# tviic2d6mddr register map
Vendor: Cypress Semiconductor; Series: tviic2d6mddr; File version: 1.0
CPU: CM7 r0p1, little endian, MPU, FPU, VTOR, 3 interrupt priority bits
Registers are 32-bit, read-write, reset 0x0 unless marked. A register's access mark holds for its fields unless they carry their own. Offsets are from the block's base; [hi:lo] are bit positions; lines under a group give offsets from that group; {n}, {i} and the like mark numbered series.

## LPDDR40 (part 1 of 5) — LPDDR4
Base 0x404A0000
0x00 LPDDR4_WRAPPER group — HOBTO specific wrapper
  0x00 CTL — Control
    [31] ENABLED — IP enable bit. When the IP is disabled, all retention registers can be accessed (else results in AHB error response). 0: Disabled. 1: Enabled.
      0=DISABLED (N/A); 1=ENABLED (N/A)
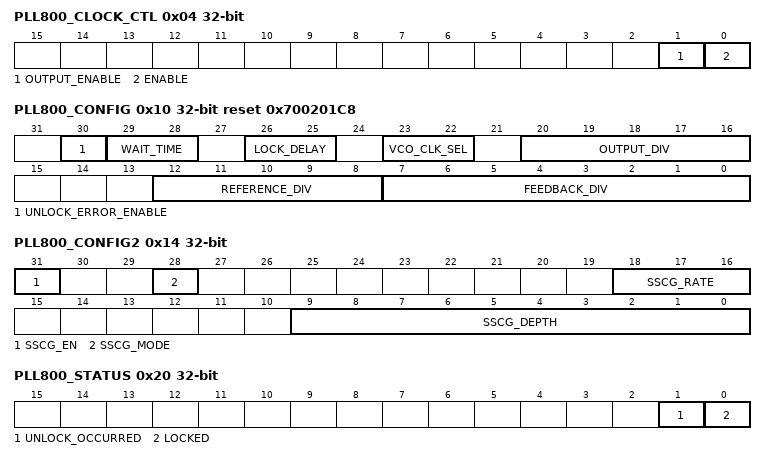
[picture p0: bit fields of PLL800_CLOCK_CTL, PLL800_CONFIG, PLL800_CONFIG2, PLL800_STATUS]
  0x04 PLL800_CLOCK_CTL — 800MHz PLL Control Register
    [1] OUTPUT_ENABLE — Control bit for clock gate at PLL output. The output clock must only be enabled after PLL800_STATUS.LOCKED was confirmed to be 1. The output clock must be stopped before changing the OUTPUT_DIV or VCO_CLK_SEL setting. 0: PLL output clock is stopped 1: PLL output clock is enabled
    [0] ENABLE — Master enable for PLL. Certain PLL800_CONFIG and PLL800_CONFIG2 registers are not allowed to be modified when the PLL is enabled (see description of individual configuration registers). 0: Block is disabled. 1: Block is enabled
  0x10 PLL800_CONFIG reset 0x700201C8 — 800MHz PLL Configuration Register
    [30] UNLOCK_ERROR_ENABLE — Control bit for the fault generation based on a PLL UNLOCK_OCCURRED event. 0: No fault event is generated when UNLOCK_OCCURRED is set 1: Setting UNLOCK_OCCURRED generates a fault event
    [29:28] WAIT_TIME — Configures the seqeuencer for starting and stopping the PLL. Set the value depending on the external oscillator frequency before enabling the PLL. 0: for 4MHz 1: for >4MHz up to 8MHz 2: for >8MHz up to 16MHz 3: for >16MHz up to 33MHz Set the register before enabling the PLL (ENABLE=1), and do not change it while PLL is enabled.
    [26:25] LOCK_DELAY
    [23:22] VCO_CLK_SEL — Select source of PLL output clock. Set the register before enabling the output clock (OUTPUT_ENABLE=1). Do not change the setting when the PLL output clock is enabled. 0: vco_clk divide by 2: fOUT = (fREF / REFERENCE_DIV) * FEEDBACK_DIV 1: vco_clk direct output: fOUT = (fREF / REFERENCE_DIV) * FEEDBACK_DIV * 2 2,3: Output divider is used: fOUT = (fREF / REFERENCE_DIV) * FEEDBACK_DIV / OUTPUT_DIV
    [20:16] OUTPUT_DIV — Control bits for Output divider. Set the divide value before enabling the output clock (OUTPUT_ENABLE=1). Do not change the setting when the PLL output clock is enabled. 0: illegal (undefined behavior) 1: illegal (undefined behavior) 2: divide by 2. ... 16: divide by 16. >16: illegal (undefined behavior)
    [12:8] REFERENCE_DIV — Control bits for reference divider. Set the divide value before enabling the PLL (ENABLE=1), and do not change it while PLL is enabled. 0: illegal (undefined behavior) 1: divide by 1 ... 18: divide by 18 others: illegal (undefined behavior)
    [7:0] FEEDBACK_DIV — Control bits for feedback divider. Set the divide value before enabling the PLL (ENABLE=1), and do not change it while PLL is enabled. 0-15: illegal (undefined behavior) 16: divide by 16 ... 200: divide by 200 >200: illegal (undefined behavior)
  0x14 PLL800_CONFIG2 — 800MHz PLL Configuration Register 2 (SSCG)
    [31] SSCG_EN — Enables spreading mode. When using spreading, see CLK_PLL800M_CONFIG.LOCK_DELAY for an additional configuration requirement. Set the register before enabling the PLL (ENABLE=1), and do not change it while PLL is enabled.
    [28] SSCG_MODE
    [18:16] SSCG_RATE — Control bits for SSCG modulation rate as a factor of fPFD clock frequency. Audio applications should choose a setting that results in a modulation rate that is greater than 20kHz, so fPFD/512 or fPFD/256 is recommended. 0: Modulation rate = fPFD/4096, 1: Modulation rate = fPFD/2048, 2: Modulation rate = fPFD/1024, 3. Modulation rate = fPFD/512, 4: Modulation rate = fPFD/256, 5: Modulation rate = fPFD/128, 6: Modulation rate = fPFD/744, 7: prohibited Set the register before enabling the PLL (ENABLE=1), and do not change it while PLL is enabled.
    [9:0] SSCG_DEPTH
  0x20 PLL800_STATUS — 800MHz PLL Status Register
    [1] UNLOCK_OCCURRED — This bit sets whenever the PLL Lock bit goes low, and stays set until cleared by firmware.
    [0] LOCKED ro — PLL Lock Indicator. Setting OUTPUT_ENABLE=1 is only permitted when this bit is 1
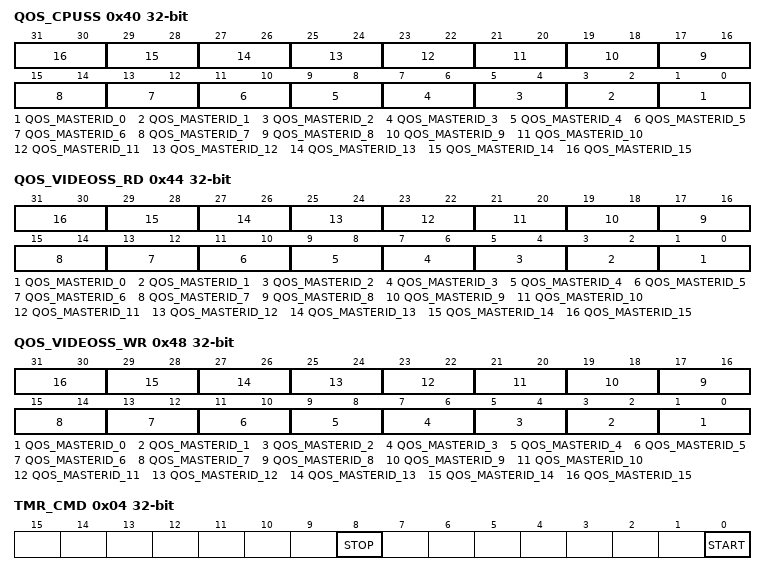
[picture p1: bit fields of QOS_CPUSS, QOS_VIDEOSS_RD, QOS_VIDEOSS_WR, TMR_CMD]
  0x40 QOS_CPUSS — QoS Configuration Register for CPUSS master
    [2n+1:2n] QOS_MASTERID_{n} (n=0..15) — QoS value of the CPUSS master ID{n}
  0x44 QOS_VIDEOSS_RD — QoS Configuration Register for VIDEOSS read master
    [2n+1:2n] QOS_MASTERID_{n} (n=0..15) — QoS value of the VIDEOSS read master ID{n}
  0x48 QOS_VIDEOSS_WR — QoS Configuration Register for VIDEOSS write master
    [2n+1:2n] QOS_MASTERID_{n} (n=0..15) — QoS value of the VIDEOSS write master ID{n}
0x400 AXI_PERF_CNT group — AXI performance counter
  0x00 CTL — Control
    [31] ENABLED — AXI performance counter enable:
      0=DISABLED ('0': Disabled. The entire AXI performance counter except the outstanding transaction counters and the MMIO registers is disabled, i.e. clock is gated and reset is asserted.); 1=ENABLED ('1': Enabled.)
  0x04 TMR_CMD — Timer command
    [8] STOP — Writing 1 to this field stops the measurement at the next clock edge of the prescaled clock. At this time, the timer count and all counters in the measurement units keep their current values. STOP is automatically cleared to 0 immediately. STOP has a lower priority than START.
    [0] START — Writing 1 to this field triggers the start of the measurement window. When this field is written to 1, MU_TMR_STATUS.MEAS in the measurement units are set to 1, indicating that the measurement window starts, and START is automatically cleared to 0. In each measurement unit, all counters are cleared to 0, and the current timer count is set to 1 and is incremented with each cycle of the prescaled clock during the measurment window. START has a higher priority than STOP. Writing 1 to this field during the measurement window restarts the measurement window, clearing the counters and restarting the timer.
  {0x200+0x40*j} MU[{j}] (j=0..1) group — Measurement unit
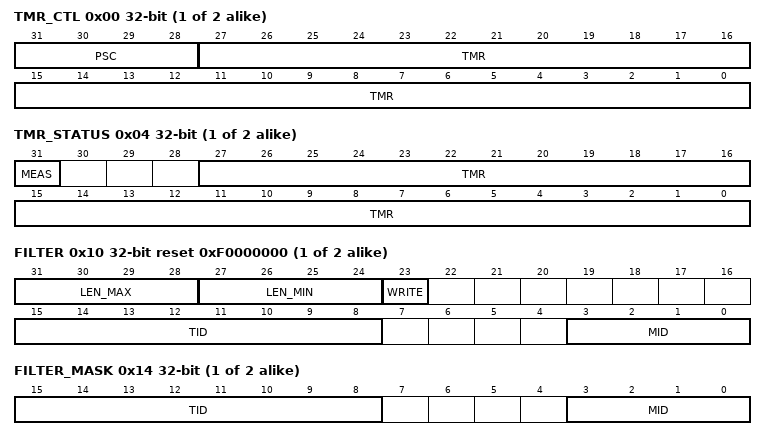
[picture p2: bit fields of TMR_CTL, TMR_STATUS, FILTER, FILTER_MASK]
    0x00 TMR_CTL — Timer control
      [31:28] PSC — 4-bit prescaler value. The clock going to the timer is divided by 2**PSC.
      [27:0] TMR — 28-bit timer value. The duration of the measurement window is (2**PSC)*TMR AXI clock cyles of the AXI port selected by PORT_SELECT.SELECT. When TMR is 0, the timer is off, and the measurement window is started by TMR_CMD.START and stopped by TMR_CMD.STOP (in this case, the duration of the measurement window needs to be measured by software).
    0x04 TMR_STATUS ro — Timer status
      [31] MEAS — This field indicates the measurement window. This field is set by writing 1 to TMR_CMD.START. It is cleared by a timer match (after TMR_STATUS.TMR * 2**TMR_CTL.PSC AXI clock cycles), or by writing 1 to TMR_CMD.STOP, at the end of the current prescaler clock period. It should be noted that the measurment takes place in a different clock domain than the MMIO clock domain, so MEAS is only a rough indication of the measurment window. The actual measurement window starts as soon as TMR_CMD.START has been synchronized to the AXI port clock domain (after MEAS goes to 1). MEAS goes to 0 after the end of the measurement window has been synchronized from the AXI port clock domain to the MMIO clock domain. Hence, MEAS is 1 for slighly longer than the real measurement domain. After writing TMR_CMD.START, MEAS can be polled immediately. When MEAS is read as 0, the timer and counter registers can be read.
      [27:0] TMR — While MEAS is 1, this field reads 0. After the end of the measurement window (MEAS = 0), this field reads the count of the timer at the end of the measurement window, unless the timer is off (TMR_CTL.TMR = 0); in this case, this field reads 0. The duration of the measurement window is TMR_STATUS.TMR * 2**TMR_CTL.PSC clock periods of the selected AXI port.
    0x08 PORT_SELECT — AXI port select
      [2:0] SELECT — This field selects the AXI port of the LPDDR4 controller on which the performance measurement is done.
    0x10 FILTER reset 0xF0000000 — Transaction filter
      [31:28] LEN_MAX — The value of this field + 1 defines the maximum burst length to be counted. This field affects the following counters: ADDR_CNT.CNT, ADDR_STALL.CNT. Note that this field does not have a corresponding field in the FILTER_MASK register.
      [27:24] LEN_MIN — The value of this field + 1 defines the minimum burst length to be counted. This field affects the following counters: ADDR_CNT.CNT, ADDR_STALL.CNT. Note that this field does not have a corresponding field in the FILTER_MASK register.
      [23] WRITE — This field sets the filter for the direction. If WRITE = 1, then only write transactions are counted, and if WRITE = 0, then only read transactions are counted. This field affects the following counters: OT_AC.CNT, ADDR_CNT.CNT, ADDR_STALL.CNT, DATA_CNT.CNT, DATA_STALL.CNT. Note that this field does not have a corresponding field in the FILTER_MASK register.
      [15:8] TID — This field sets the filter for the upper transaction ID. Only bits i for which FILTER_MASK.TID[i] is 1 are compared. This field affects the following counters: ADDR.CNT, ADDR_STALL.CNT, DATA.CNT, DATA_STALL.CNT. Note: If WRITE = 1, this field has no effect on DATA_CNT and DATA_STALL_CNT. Note: TID denotes bits [ID_WIDTH-1:8] of the transaction ID. Different ports can have different ID widths. ID_WIDTH is the ID width of the port with the largest ID width. For ports with smaller ID widths, the MSBs of TID are '0'.
      [3:0] MID — This field sets the filter for the Master ID. Only bits i for which FILTER_MASK.MID[i] is 1 are compared. This field affects the following counters: ADDR_CNT.CNT, ADDR_STALL.CNT, DATA_CNT.CNT, DATA_STALL.CNT. Note: If WRITE = 1, this field has no effect on DATA_CNT and DATA_STALL_CNT.
    0x14 FILTER_MASK — Transaction filter mask
      [15:8] TID — This field sets the filter for the upper transaction ID. Only bits i for which TID[i] is 1 are compared with FILTER.TID[i]. This field affects the following counters: ADDR_CNT.CNT, ADDR_STALL.CNT, DATA_CNT.CNT, DATA_STALL.CNT. Note: If FILTER.WRITE = 1, this field has no effect on DATA_CNT.CNT and DATA_STALL_CNT. Note: TID denotes bits [ID_WIDTH-1:8] of the transaction ID. Different ports can have different ID widths. ID_WIDTH is the ID width of the port with the largest ID width. For ports with smaller ID widths, the MSBs of TID are '0'.
      [3:0] MID — This field sets the filter mask for the Master ID. Only bits i for which MID[i] is 1 are compared with FILTER.MID[i]. This field affects the following counters: ADDR_CNT.CNT, ADDR_STALL.CNT, DATA_CNT.CNT, DATA_STALL.CNT. Note: If FILTER.WRITE = 1, this field has no effect on DATA_CNT.CNT and DATA_STALL_CNT.
    0x18 OT_AC ro — Accumulated outstanding transactions
      [31:0] CNT — While TMR_STATUS.MEAS is 1, this field reads 0. While TMR_STATUS.MEAS is 0, this field reads the accumulated number of outstanding read or write transactions during the measurement window, depending on FILTER.WRITE. This counter is cleared by TMR_CMD.START. During the measurement window, this counter is incremented in each AXI clock cycle by the current number of outstanding read or write transactions. If FILTER.WRITE = 0, this counter accumulates the outstanding read transactions. If FILTER.WRITE = 1, this counter accumulates the outstanding write transactions. Instead of overflowing, this counter is clipped at 0xFFFFFFFF. This means that if at the end of the measurement window, a count of 0xFFFFFFFF is read, then it is very likely that this counter has overflowed. In this case, a shorter measurement window should be used.
    0x20 ADDR_CNT ro — Address transfer counter
      [31:0] CNT — While TMR_STATUS.MEAS is 1, this field reads 0. While TMR_STATUS.MEAS is 0, this field reads the value of the address transfer counter. This counter shows the number of filtered address transfers during the measurement window. This counter is cleared by TMR_CMD.START. During the measurement window, this counter is incremented by each address transfer that passes the filter defined by FILTER and FILTER_MASK. Instead of overflowing, this counter is clipped at 0xFFFFFFFF. This means that if at the end of the measurement window, a count of 0xFFFFFFFF is read, then it is very likely that this counter has overflowed. In this case, a shorter measurement window should be used.
    0x24 ADDR_STALL_CNT ro — Address stall counter
      [31:0] CNT — While TMR_STATUS.MEAS is 1, this field reads 0. While TMR_STATUS.MEAS is 0, this field reads the value of the address stall counter. This counter shows the number of filtered address stall cycles during the measurement window. This counter is cleared by TMR_CMD.START. During the measurement window, this counter is incremented by each address stall cycle that passes the filter defined by FILTER and FILTER_MASK. Instead of overflowing, this counter is clipped at 0xFFFFFFFF. This means that if at the end of the measurement window, a count of 0xFFFFFFFF is read, then it is very likely that this counter has overflowed. In this case, a shorter measurement window should be used.
    0x28 DATA_CNT ro — Data transfer counter
      [31:0] CNT — While TMR_STATUS.MEAS is 1, this field reads 0. While TMR_STATUS.MEAS is 0, this field reads the value of the data transfer counter. This counter shows the number of filtered data transfers during the measurement window. This counter is cleared by TMR_CMD.START. During the measurement window, this counter is incremented by each data transfer that passes the filter defined by FILTER and FILTER_MASK. It should be noted that if FILTER.WRITE = 1, the write data are not filtered by master ID and upper transaction ID. Instead of overflowing, this counter is clipped at 0xFFFFFFFF. This means that if at the end of the measurement window, a count of 0xFFFFFFFF is read, then it is very likely that this counter has overflowed. In this case, a shorter measurement window should be used.
    0x2C DATA_STALL_CNT ro — Data stall counter
      [31:0] CNT — While TMR_STATUS.MEAS is 1, this field reads 0. While TMR_STATUS.MEAS is 0, this field reads the value of the data stall counter.This counter shows the number of filtered data stall cycles during the measurement window. This counter is cleared by TMR_CMD.START. While TMR_STATUS.MEAS = 1, this counter is incremented by each data stall cycle that passes the filter defined by FILTER and FILTER_MASK. . It should be noted that if FILTER.WRITE = 1, the write data are not filtered by master ID and upper transaction ID. Instead of overflowing, this counter is clipped at 0xFFFFFFFF. This means that if at the end of the measurement window, a count of 0xFFFFFFFF is read, then it is very likely that this counter has overflowed. In this case, a shorter measurement window should be used.
